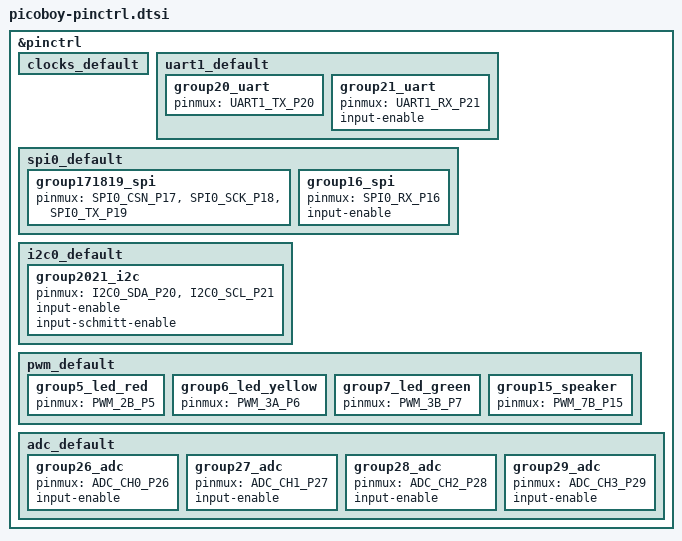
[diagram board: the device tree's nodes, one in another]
/*
 * SPDX-FileCopyrightText: Copyright (c) 2023-2026 TiaC Systems
 * SPDX-License-Identifier: Apache-2.0
 */

#include <zephyr/dt-bindings/pinctrl/rpi-pico-rp2040-pinctrl.h>

&pinctrl {
	clocks_default: clocks_default {
		/* no external clocks */
	};

	uart1_default: uart1_default {			/* alt: sensors */
		group20_uart {				/* as UART i/f */
			pinmux = <UART1_TX_P20>;
		};
		group21_uart {
			pinmux = <UART1_RX_P21>;
			input-enable;
		};
	};

	spi0_default: spi0_default {
		group171819_spi {
			pinmux = <SPI0_CSN_P17>,	/* not wired */
				 <SPI0_SCK_P18>,	/* OLED display */
				 <SPI0_TX_P19>;		/* SH1106 (128x64) */
		};
		group16_spi {
			pinmux = <SPI0_RX_P16>;		/* not wired */
			input-enable;
		};
	};

	i2c0_default: i2c0_default {
		group2021_i2c {
			pinmux = <I2C0_SDA_P20>,	/* acceleration */
				 <I2C0_SCL_P21>;	/* sensor STK8BA58 */
			input-enable;
			input-schmitt-enable;
		};
	};

	pwm_default: pwm_default {
		group5_led_red {
			pinmux = <PWM_2B_P5>;		/* Red LED */
		};
		group6_led_yellow {
			pinmux = <PWM_3A_P6>;		/* Yellow LED */
		};
		group7_led_green {
			pinmux = <PWM_3B_P7>;		/* Green LED */
		};
		group15_speaker {
			pinmux = <PWM_7B_P15>;		/* Speaker */
		};
	};

	adc_default: adc_default {
		group26_adc {
			pinmux = <ADC_CH0_P26>;
			input-enable;
		};
		group27_adc {
			pinmux = <ADC_CH1_P27>;
			input-enable;
		};
		group28_adc {
			pinmux = <ADC_CH2_P28>;
			input-enable;
		};
		group29_adc {
			pinmux = <ADC_CH3_P29>;
			input-enable;
		};
	};
};
